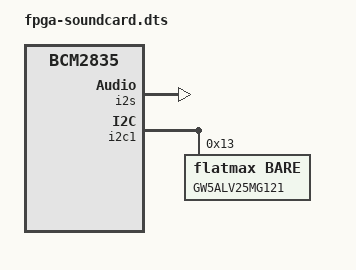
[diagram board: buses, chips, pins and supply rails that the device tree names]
/dts-v1/;
/plugin/;

/* Device Tree Overlay for generic I2S audio output on Raspberry Pi
*/

/ {
    compatible = "brcm,bcm2835";

    fragment@0 {
        target = <&sound>;
        __overlay__ {

            compatible = "simple-audio-card";
            simple-audio-card,name = "FPGA-Soundcard";
			
            status="okay";

            playback_link: simple-audio-card,dai-link@1 {
                format = "i2s";

                bitclock-master = <&p_codec_dai>;
                frame-master = <&p_codec_dai>;

                p_cpu_dai: cpu {
                    sound-dai = <&i2s>;
                    dai-tdm-slot-num = <2>;
                    dai-tdm-slot-width = <32>;
                };

                p_codec_dai: codec {
                    sound-dai = <&GW5ALV25MG121>;
                };
            };
        };
    };

    fragment@1 {
        target = <&i2s>;
        __overlay__ {
            #sound-dai-cells = <0>;
            status = "okay";
        };
    };

    fragment@2{
	target= <&i2c1>;
	__overlay__ {
            #address-cells = <1>;
    	#sound-dai-cells = <0>;
            #size-cells = <0>;
	    status = "okay";

	    GW5ALV25MG121: codec@13 {
                #sound-dai-cells = <0>;
		compatible = "flatmax,bare";
		reg = <0x13>;
		status = "okay";
		/* clocks =<&>; */
	    };
	};
    };
};
